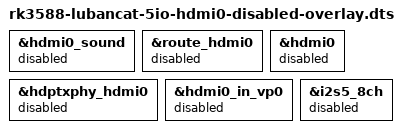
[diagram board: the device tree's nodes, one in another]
/dts-v1/;
/plugin/;

#include <dt-bindings/gpio/gpio.h>
#include <dt-bindings/pinctrl/rockchip.h>
#include <dt-bindings/display/drm_mipi_dsi.h>
#include <dt-bindings/interrupt-controller/irq.h>

/ {
	fragment@0 {
		target = <&hdmi0_sound>;

		__overlay__ {
			status = "disabled";
		};
	};

	fragment@1 {
		target = <&route_hdmi0>;

		__overlay__ {
			status = "disabled";
		};
	};

	fragment@2 {
		target = <&hdmi0>;

		__overlay__ {
			status = "disabled";
		};
	};

	fragment@3 {
		target = <&hdptxphy_hdmi0>;

		__overlay__ {
			status = "disabled";
		};
	};

	fragment@4 {
		target = <&hdmi0_in_vp0>;

		__overlay__ {
			status = "disabled";
		};
	};

	fragment@5 {
		target = <&i2s5_8ch>;

		__overlay__ {
			status = "disabled";
		};
	};
};
